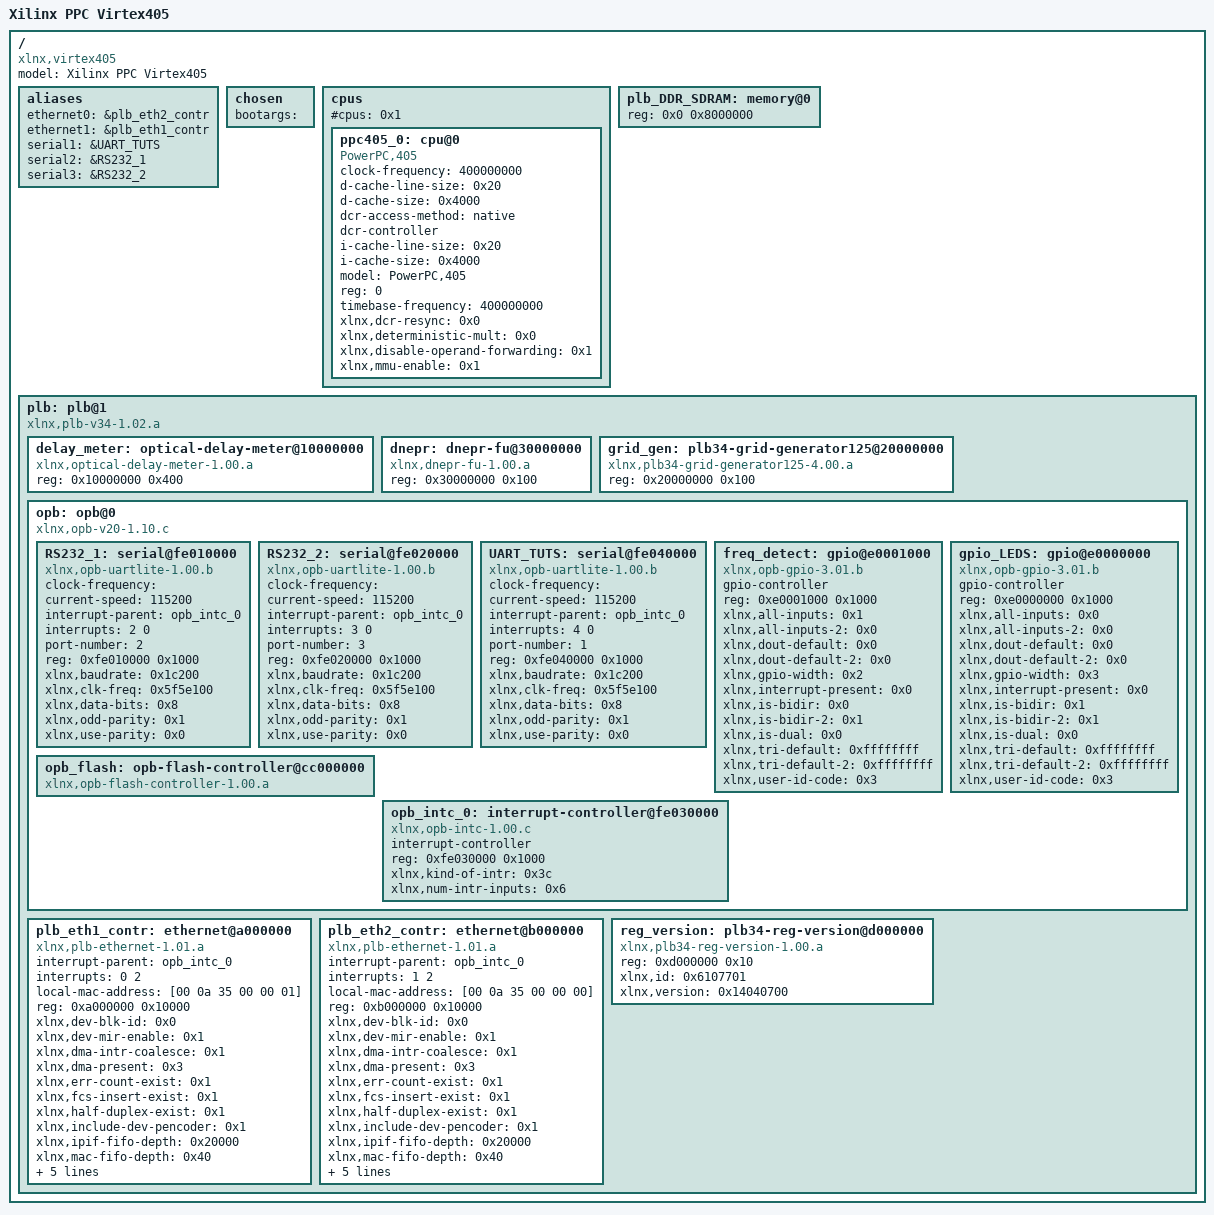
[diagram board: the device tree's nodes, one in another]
/*
 * Device Tree Generator version: 1.1
 *
 * (C) Copyright 2007-2013 Xilinx, Inc.
 * (C) Copyright 2007-2013 Michal Simek
 * (C) Copyright 2007-2012 PetaLogix Qld Pty Ltd
 *
 * Michal SIMEK <monstr@monstr.eu>
 *
 * CAUTION: This file is automatically generated by libgen.
 * Version: Xilinx EDK 10.1.03 EDK_K_SP3.6
 * Today is: Среда, the 21 of Май, 2014; 19:32:09
 *
 * XPS project directory: ppc405_0_sw_platform
 */

/dts-v1/;
/ {
	#address-cells = <1>;
	#size-cells = <1>;
	compatible = "xlnx,virtex405", "xlnx,virtex";
	model = "Xilinx PPC Virtex405";
	aliases {
		ethernet0 = &plb_eth2_contr;
		ethernet1 = &plb_eth1_contr;
		serial1 = &UART_TUTS;
		serial2 = &RS232_1;
		serial3 = &RS232_2;
	} ;
	chosen {
		bootargs = "";
	} ;
	cpus {
		#address-cells = <1>;
		#cpus = <0x1>;
		#size-cells = <0>;
		ppc405_0: cpu@0 {
			clock-frequency = <400000000>;
			compatible = "PowerPC,405", "ibm,ppc405";
			d-cache-line-size = <0x20>;
			d-cache-size = <0x4000>;
			dcr-access-method = "native";
			dcr-controller ;
			device_type = "cpu";
			i-cache-line-size = <0x20>;
			i-cache-size = <0x4000>;
			model = "PowerPC,405";
			reg = <0>;
			timebase-frequency = <400000000>;
			xlnx,dcr-resync = <0x0>;
			xlnx,deterministic-mult = <0x0>;
			xlnx,disable-operand-forwarding = <0x1>;
			xlnx,mmu-enable = <0x1>;
		} ;
	} ;
	plb_DDR_SDRAM: memory@0 {
		device_type = "memory";
		reg = <0x0 0x8000000>;
	} ;
	plb: plb@1 {
		#address-cells = <1>;
		#size-cells = <1>;
		compatible = "xlnx,plb-v34-1.02.a", "simple-bus";
		ranges ;
		delay_meter: optical-delay-meter@10000000 {
			compatible = "xlnx,optical-delay-meter-1.00.a";
			reg = <0x10000000 0x400>;
		} ;
		dnepr: dnepr-fu@30000000 {
			compatible = "xlnx,dnepr-fu-1.00.a";
			reg = <0x30000000 0x100>;
		} ;
		grid_gen: plb34-grid-generator125@20000000 {
			compatible = "xlnx,plb34-grid-generator125-4.00.a";
			reg = <0x20000000 0x100>;
		} ;
		opb: opb@0 {
			#address-cells = <1>;
			#size-cells = <1>;
			compatible = "xlnx,opb-v20-1.10.c", "simple-bus";
			ranges = <0xc0000000 0xc0000000 0x40000000>;
			RS232_1: serial@fe010000 {
				clock-frequency = "";
				compatible = "xlnx,opb-uartlite-1.00.b";
				current-speed = <115200>;
				device_type = "serial";
				interrupt-parent = <&opb_intc_0>;
				interrupts = <2 0>;
				port-number = <2>;
				reg = <0xfe010000 0x1000>;
				xlnx,baudrate = <0x1c200>;
				xlnx,clk-freq = <0x5f5e100>;
				xlnx,data-bits = <0x8>;
				xlnx,odd-parity = <0x1>;
				xlnx,use-parity = <0x0>;
			} ;
			RS232_2: serial@fe020000 {
				clock-frequency = "";
				compatible = "xlnx,opb-uartlite-1.00.b";
				current-speed = <115200>;
				device_type = "serial";
				interrupt-parent = <&opb_intc_0>;
				interrupts = <3 0>;
				port-number = <3>;
				reg = <0xfe020000 0x1000>;
				xlnx,baudrate = <0x1c200>;
				xlnx,clk-freq = <0x5f5e100>;
				xlnx,data-bits = <0x8>;
				xlnx,odd-parity = <0x1>;
				xlnx,use-parity = <0x0>;
			} ;
			UART_TUTS: serial@fe040000 {
				clock-frequency = "";
				compatible = "xlnx,opb-uartlite-1.00.b";
				current-speed = <115200>;
				device_type = "serial";
				interrupt-parent = <&opb_intc_0>;
				interrupts = <4 0>;
				port-number = <1>;
				reg = <0xfe040000 0x1000>;
				xlnx,baudrate = <0x1c200>;
				xlnx,clk-freq = <0x5f5e100>;
				xlnx,data-bits = <0x8>;
				xlnx,odd-parity = <0x1>;
				xlnx,use-parity = <0x0>;
			} ;
			freq_detect: gpio@e0001000 {
				#gpio-cells = <2>;
				compatible = "xlnx,opb-gpio-3.01.b";
				gpio-controller ;
				reg = <0xe0001000 0x1000>;
				xlnx,all-inputs = <0x1>;
				xlnx,all-inputs-2 = <0x0>;
				xlnx,dout-default = <0x0>;
				xlnx,dout-default-2 = <0x0>;
				xlnx,gpio-width = <0x2>;
				xlnx,interrupt-present = <0x0>;
				xlnx,is-bidir = <0x0>;
				xlnx,is-bidir-2 = <0x1>;
				xlnx,is-dual = <0x0>;
				xlnx,tri-default = <0xffffffff>;
				xlnx,tri-default-2 = <0xffffffff>;
				xlnx,user-id-code = <0x3>;
			} ;
			gpio_LEDS: gpio@e0000000 {
				#gpio-cells = <2>;
				compatible = "xlnx,opb-gpio-3.01.b";
				gpio-controller ;
				reg = <0xe0000000 0x1000>;
				xlnx,all-inputs = <0x0>;
				xlnx,all-inputs-2 = <0x0>;
				xlnx,dout-default = <0x0>;
				xlnx,dout-default-2 = <0x0>;
				xlnx,gpio-width = <0x3>;
				xlnx,interrupt-present = <0x0>;
				xlnx,is-bidir = <0x1>;
				xlnx,is-bidir-2 = <0x1>;
				xlnx,is-dual = <0x0>;
				xlnx,tri-default = <0xffffffff>;
				xlnx,tri-default-2 = <0xffffffff>;
				xlnx,user-id-code = <0x3>;
			} ;
			opb_flash: opb-flash-controller@cc000000 {
				#address-cells = <1>;
				#size-cells = <1>;
				compatible = "xlnx,opb-flash-controller-1.00.a";
				ranges = <0xcc000000 0xcc000000 0x4000000 0xd0000000 0xd0000000 0x4000000 0xd4000000 0xd4000000 0x4000000 0xd8000000 0xd8000000 0x4000000>;
			} ;
			opb_intc_0: interrupt-controller@fe030000 {
				#interrupt-cells = <0x2>;
				compatible = "xlnx,opb-intc-1.00.c", "xlnx,xps-intc-1.00.a";
				interrupt-controller ;
				reg = <0xfe030000 0x1000>;
				xlnx,kind-of-intr = <0x3c>;
				xlnx,num-intr-inputs = <0x6>;
			} ;
		} ;
		plb_eth1_contr: ethernet@a000000 {
			compatible = "xlnx,plb-ethernet-1.01.a";
			device_type = "network";
			interrupt-parent = <&opb_intc_0>;
			interrupts = <0 2>;
			local-mac-address = [00 0a 35 00 00 01];
			reg = <0xa000000 0x10000>;
			xlnx,dev-blk-id = <0x0>;
			xlnx,dev-mir-enable = <0x1>;
			xlnx,dma-intr-coalesce = <0x1>;
			xlnx,dma-present = <0x3>;
			xlnx,err-count-exist = <0x1>;
			xlnx,fcs-insert-exist = <0x1>;
			xlnx,half-duplex-exist = <0x1>;
			xlnx,include-dev-pencoder = <0x1>;
			xlnx,ipif-fifo-depth = <0x20000>;
			xlnx,mac-fifo-depth = <0x40>;
			xlnx,mii-exist = <0x1>;
			xlnx,miim-clkdvd = <0x13>;
			xlnx,pad-insert-exist = <0x1>;
			xlnx,reset-present = <0x1>;
			xlnx,source-addr-insert-exist = <0x1>;
		} ;
		plb_eth2_contr: ethernet@b000000 {
			compatible = "xlnx,plb-ethernet-1.01.a";
			device_type = "network";
			interrupt-parent = <&opb_intc_0>;
			interrupts = <1 2>;
			local-mac-address = [00 0a 35 00 00 00];
			reg = <0xb000000 0x10000>;
			xlnx,dev-blk-id = <0x0>;
			xlnx,dev-mir-enable = <0x1>;
			xlnx,dma-intr-coalesce = <0x1>;
			xlnx,dma-present = <0x3>;
			xlnx,err-count-exist = <0x1>;
			xlnx,fcs-insert-exist = <0x1>;
			xlnx,half-duplex-exist = <0x1>;
			xlnx,include-dev-pencoder = <0x1>;
			xlnx,ipif-fifo-depth = <0x20000>;
			xlnx,mac-fifo-depth = <0x40>;
			xlnx,mii-exist = <0x1>;
			xlnx,miim-clkdvd = <0x13>;
			xlnx,pad-insert-exist = <0x1>;
			xlnx,reset-present = <0x1>;
			xlnx,source-addr-insert-exist = <0x1>;
		} ;
		reg_version: plb34-reg-version@d000000 {
			compatible = "xlnx,plb34-reg-version-1.00.a";
			reg = <0xd000000 0x10>;
			xlnx,id = <0x6107701>;
			xlnx,version = <0x14040700>;
		} ;
	} ;
} ;
